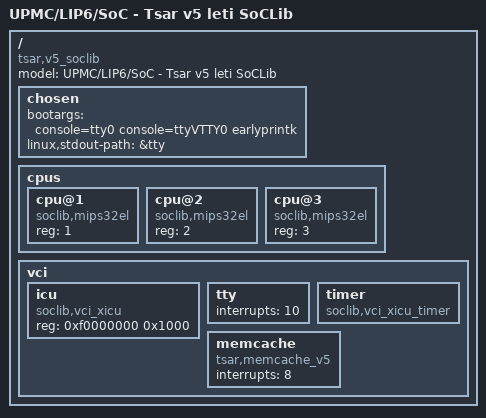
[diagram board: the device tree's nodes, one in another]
/*
 * DTS file for TSARV5 leti on SoCLib
 *
 * Includes the skeleton and specializes it:
 *  - add 3 cpus
 */

/dts-v1/;

/include/ "tsar_skeleton_leti.dtsi"

/ {
	model = "UPMC/LIP6/SoC - Tsar v5 leti SoCLib";
	compatible = "tsar,v5_soclib", "tsar,leti_v5_soclib";

	chosen {
		/* the day we have a uart8250 compatible component, we can use
		 * the earlycon param to get earlyprintk */
		/* bootargs = "earlycon=uart8250,mmio,0x00000000"; */

		/* this is for maximum debug */
		/* bootargs = "ignore_loglevel initcall_debug"; */

		/* display console in both framebuffer and tty (the last one
		 * becomes the default one) */
		bootargs = "console=tty0 console=ttyVTTY0 earlyprintk";

		/* default peripheral to use when configuring earlyprintk */
		linux,stdout-path = &tty;
	};

	cpus {
		cpu@1 {
			device_type = "cpu";
			compatible = "soclib,mips32el";
			reg = <1>;
		};
		cpu@2 {
			device_type = "cpu";
			compatible = "soclib,mips32el";
			reg = <2>;
		};
		cpu@3 {
			device_type = "cpu";
			compatible = "soclib,mips32el";
			reg = <3>;
		};
	};

	vci {
		icu: icu {
			/* the vci_xicu is a N->N interrupt controller,
			 * with support for IPI */

			/* warning: in leti system the vci_xicu is a N*4->N
			 * interrupt controller */

			compatible = "soclib,vci_xicu";
			reg = <0xf0000000 0x1000>;
		};

		tty: tty {
			interrupts = <10>;
		};

		timer {
			compatible = "soclib,vci_xicu_timer";
		};

		/*
		blockdevice {
			compatible = "tsar,vci_block_device_tsar_v5";
			reg = <0x1c000000 0x40>;
			interrupts = <9>;
		};
		*/

		memcache {
			compatible = "tsar,memcache_v5";
			interrupts = <8>;
		};
	};
};

